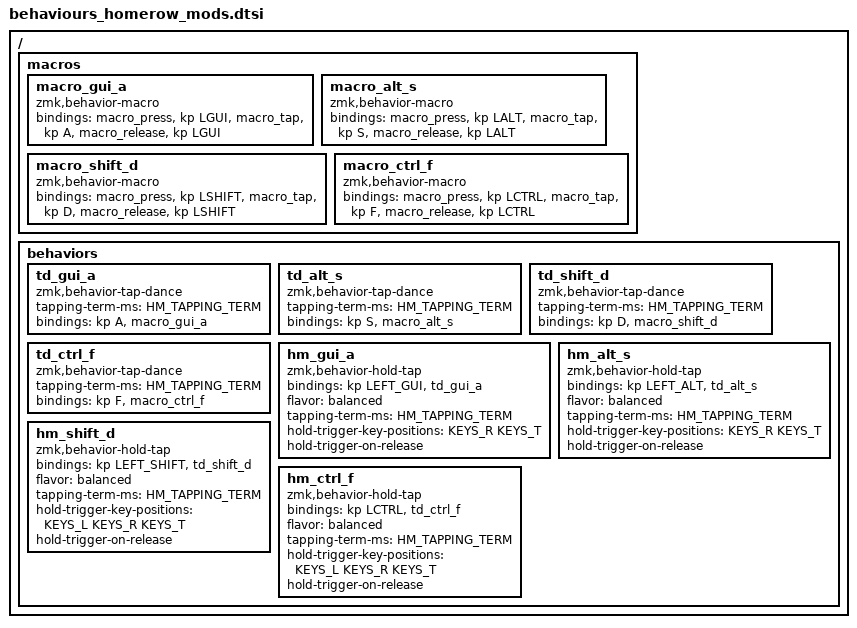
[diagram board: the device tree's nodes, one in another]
// Make sure settings.dtsi is included before this file

#define HM_TAPPING_TERM 200
#define HM_TAPPING_TERM_FAST 200
#define HM_PRIOR_IDLE 150

#include "zmk-helpers/key-labels/42.h"
#define KEYS_L LT0 LT1 LT2 LT3 LT4 LT5 LM0 LM1 LM2 LM3 LM4 LM5 LB0 LB1 LB2 LB3 LB4 LB5
#define KEYS_R RT0 RT1 RT2 RT3 RT4 RT5 RM0 RM1 RM2 RM3 RM4 RM5 RB0 RB1 RB2 RB3 RB4 RB5
#define KEYS_T LH2 LH1 LH0 RH0 RH1 RH2

/ {

    macros {
        // Macros for mod+key combinations
        macro_gui_a: macro_gui_a {
            compatible = "zmk,behavior-macro";
            #binding-cells = <0>;
            bindings = <&macro_press &kp LGUI>
                     , <&macro_tap &kp A>
                     , <&macro_release &kp LGUI>;
        };

        macro_alt_s: macro_alt_s {
            compatible = "zmk,behavior-macro";
            #binding-cells = <0>;
            bindings = <&macro_press &kp LALT>
                     , <&macro_tap &kp S>
                     , <&macro_release &kp LALT>;
        };

        macro_shift_d: macro_shift_d {
            compatible = "zmk,behavior-macro";
            #binding-cells = <0>;
            bindings = <&macro_press &kp LSHIFT>
                     , <&macro_tap &kp D>
                     , <&macro_release &kp LSHIFT>;
        };

        macro_ctrl_f: macro_ctrl_f {
            compatible = "zmk,behavior-macro";
            #binding-cells = <0>;
            bindings = <&macro_press &kp LCTRL>
                     , <&macro_tap &kp F>
                     , <&macro_release &kp LCTRL>;
        };
    };

    behaviors {

        // Tap-dance behaviors for each homerow key
        // Single tap = key, Double tap = mod+key
        td_gui_a: td_gui_a {
            compatible = "zmk,behavior-tap-dance";
            #binding-cells = <0>;
            tapping-term-ms = <HM_TAPPING_TERM>;
            bindings = <&kp A>, <&macro_gui_a>;
        };

        td_alt_s: td_alt_s {
            compatible = "zmk,behavior-tap-dance";
            #binding-cells = <0>;
            tapping-term-ms = <HM_TAPPING_TERM>;
            bindings = <&kp S>, <&macro_alt_s>;
        };

        td_shift_d: td_shift_d {
            compatible = "zmk,behavior-tap-dance";
            #binding-cells = <0>;
            tapping-term-ms = <HM_TAPPING_TERM>;
            bindings = <&kp D>, <&macro_shift_d>;
        };

        td_ctrl_f: td_ctrl_f {
            compatible = "zmk,behavior-tap-dance";
            #binding-cells = <0>;
            tapping-term-ms = <HM_TAPPING_TERM>;
            bindings = <&kp F>, <&macro_ctrl_f>;
        };

        // Homerow mod behaviors wrapping tap-dance
        // Hold = mod, Tap/Double-tap = handled by tap-dance
        hm_gui_a: hm_gui_a {
            compatible = "zmk,behavior-hold-tap";
            #binding-cells = <0>;
            bindings = <&kp LEFT_GUI>, <&td_gui_a>;
            
            flavor = "balanced";
            tapping-term-ms = <HM_TAPPING_TERM>;
            hold-trigger-key-positions = <KEYS_R KEYS_T>;
            hold-trigger-on-release;
        };

        hm_alt_s: hm_alt_s {
            compatible = "zmk,behavior-hold-tap";
            #binding-cells = <0>;
            bindings = <&kp LEFT_ALT>, <&td_alt_s>;
            
            flavor = "balanced";
            tapping-term-ms = <HM_TAPPING_TERM>;
            hold-trigger-key-positions = <KEYS_R KEYS_T>;
            hold-trigger-on-release;
        };

        hm_shift_d: hm_shift_d {
            compatible = "zmk,behavior-hold-tap";
            #binding-cells = <0>;
            bindings = <&kp LEFT_SHIFT>, <&td_shift_d>;
            
            flavor = "balanced";
            tapping-term-ms = <HM_TAPPING_TERM>;
            hold-trigger-key-positions = <KEYS_L KEYS_R KEYS_T>;
            hold-trigger-on-release;
        };

        hm_ctrl_f: hm_ctrl_f {
            compatible = "zmk,behavior-hold-tap";
            #binding-cells = <0>;
            bindings = <&kp LCTRL>, <&td_ctrl_f>;
            
            flavor = "balanced";
            tapping-term-ms = <HM_TAPPING_TERM>;
            hold-trigger-key-positions = <KEYS_L KEYS_R KEYS_T>;
            hold-trigger-on-release;
        };
    };
};
